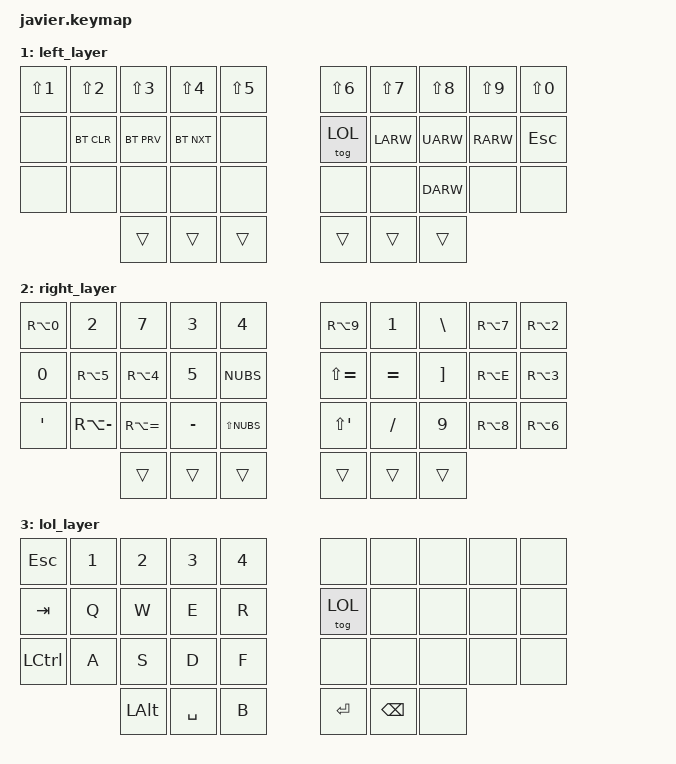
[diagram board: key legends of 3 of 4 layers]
#include <behaviors.dtsi>
#include <dt-bindings/zmk/keys.h>
#include <dt-bindings/zmk/bt.h>

#define DEF 0
#define LEF 1
#define RIG 2
// #define TRI 3
#define LOL 3

// Home row mod macros
#define HRML(k1,k2,k3,k4) &ht LSHIFT k1 &ht LGUI k2  &ht LCTRL k3  &ht LSHIFT k4
#define HRMR(k1,k2,k3,k4) &ht RSHIFT k1  &ht RCTRL k2  &ht RALT k3 &ht RSHIFT k4

/ {
    behaviors {
        ht: hold_tap {
            label = "hold_tap";
            compatible = "zmk,behavior-hold-tap";
            #binding-cells = <2>;
            flavor = "balanced";
            tapping-term-ms = <200>;
            bindings = <&kp>, <&kp>;
        };

        dashes: dashes {
            compatible = "zmk,behavior-mod-morph";
            #binding-cells = <0>;
            bindings = <&kp N6>, <&kp N8>;
            mods = <(MOD_LSFT|MOD_RSFT)>;
            keep-mods = <(MOD_RSFT)>;
        };
    };
    // conditional_layers {
    //     compatible = "zmk,conditional-layers";
    //     tri_layer {
    //         if-layers = <RIG LEF>;
    //         then-layer = <TRI>;
    //     };
    // };

    keymap {
        compatible = "zmk,keymap";

        default_layer {
            bindings = <
        //╭──────────┬──────────┬──────────┬──────────┬──────────╮   ╭──────────┬──────────┬──────────┬──────────┬──────────╮
        //│  A       │  Z       │  E       │  R       │  T       │   │  Y       │  U       │  I       │  O       │  P       │
            &kp Q      &kp W      &kp E      &kp R      &kp T          &kp Y      &kp U      &kp I      &kp O      &kp P
        //├──────────┼──────────┼──────────┼──────────┼──────────┤   ├──────────┼──────────┼──────────┼──────────┼──────────┤
        //│  Q       │  S       │  D       │  F       │  G       │   │  H       │  J       │  K       │  L       │  M       │
            HRML(A,     S,         D,         F)        &kp G          &kp H      HRMR(J,     K,         L,         SEMI)
        //├──────────┼──────────┼──────────┼──────────┼──────────┤   ├──────────┼──────────┼──────────┼──────────┼──────────┤
        //│  W       │  X       │  C       │  V       │  B       │   │  N       │  , ?     │  ; .     │  : /     │   - _    │
          &ht LCTRL Z   &kp X      &kp C      &kp V      &kp B          &kp N     &kp M      &kp COMMA    &kp DOT   &dashes
        //╰──────────┴──────────┴──────────┼──────────┼──────────┤   ├──────────┼──────────┼──────────┴──────────┴──────────╯
                                &ht LCTRL ESC &kp SPACE &lt LEF TAB   &lt RIG RET  &kp BSPC  &kp LALT
        //                      ╰──────────┴──────────┴──────────╯   ╰──────────┴──────────┴──────────╯
            >;
        };

        left_layer {
            bindings = <
        //╭──────────┬──────────┬──────────┬──────────┬──────────╮   ╭──────────┬──────────┬──────────┬──────────┬──────────╮
        //│ 1        │  2       │  3       │  4       │  5       │   │ 6        │ 7        │ 8        │ 9        │   0      │
          &kp LS(N1)  &kp LS(N2) &kp LS(N3) &kp LS(N4) &kp LS(N5)     &kp LS(N6) &kp LS(N7) &kp LS(N8) &kp LS(N9) &kp LS(N0)
        //├──────────┼──────────┼──────────┼──────────┼──────────┤   ├──────────┼──────────┼──────────┼──────────┼──────────┤
        //│          │ BT CLEAR │ BT PREV  │ BT NEXT  │          |   | LOL      │ LEFT     │ UP       │ RIGHT    │ ESC      │
            &none     &bt BT_CLR &bt BT_PRV &bt BT_NXT &none           &tog LOL  &kp LARW   &kp UARW   &kp RARW   &kp ESC 
        //├──────────┼──────────┼──────────┼──────────┼──────────┤   ├──────────┼──────────┼──────────┼──────────┼──────────┤
        //│          │          │          │          │          │   │          │          │ DOWN     │          │          │
            &none     &none      &none      &none       &none          &none      &none      &kp DARW   &none      &none 
        //╰──────────┴──────────┴──────────┼──────────┼──────────┤   ├──────────┼──────────┼──────────┴──────────┴──────────╯
                                  &trans     &trans     &trans         &trans     &trans     &trans  
        //                      ╰──────────┴──────────┴──────────╯   ╰──────────┴──────────┴──────────╯
            >;
        };

        right_layer {
            bindings = <
        //╭──────────┬──────────┬──────────┬──────────┬──────────╮   ╭──────────┬──────────┬──────────┬──────────┬──────────╮
        //│  @       │  é       │  è       │  "       │  '       │   │  ^       │  &       │  *       │  `       │  ~       │
          &kp RA(N0)    &kp N2     &kp N7    &kp N3     &kp N4        &kp RA(N9)   &kp N1    &kp BSLH  &kp RA(N7) &kp RA(N2)
        //├──────────┼──────────┼──────────┼──────────┼──────────┤   ├──────────┼──────────┼──────────┼──────────┼──────────┤
        //│  à       │  [       │  {       │  (       │   <      │   │  +       │  =       │  $       │   €      │  #       │
            &kp N0    &kp RA(N5)  &kp RA(N4)   &kp N5   &kp NUBS    &kp LS(EQUAL) &kp EQUAL  &kp RBKT  &kp RA(E)   &kp RA(N3)
        //├──────────┼──────────┼──────────┼──────────┼──────────┤   ├──────────┼──────────┼──────────┼──────────┼──────────┤
        //│  ù       │  ]       │  }       │  )       │   >      │   │   %      │  !       │  ç       │  \       │   |      │
           &kp SQT  &kp RA(MINUS) &kp RA(EQUAL) &kp MINUS &kp LS(NUBS) &kp LS(SQT) &kp FSLH  &kp N9    &kp RA(N8) &kp RA(N6)
        //╰──────────┴──────────┴──────────┼──────────┼──────────┤   ├──────────┼──────────┼──────────┴──────────┴──────────╯
                                  &trans     &trans     &trans         &trans     &trans     &trans 
        //                      ╰──────────┴──────────┴──────────╯   ╰──────────┴──────────┴──────────╯
            >;
        };

        lol_layer {
            bindings = <
        //╭──────────┬──────────┬──────────┬──────────┬──────────╮   ╭──────────┬──────────┬──────────┬──────────┬──────────╮
        //│ ESC      │  1       │  2       │  3       │  4       │   │          │          │          │          │          │
           &kp ESC    &kp N1     &kp N2     &kp N3      &kp N4         &none      &none       &none      &none      &none
        //├──────────┼──────────┼──────────┼──────────┼──────────┤   ├──────────┼──────────┼──────────┼──────────┼──────────┤
        //│  TAB     │  A       │  Z       │  E       │  R       |   | LOL      │          │          │          │          │
            &kp TAB    &kp Q      &kp W      &kp E     &kp R           &tog LOL   &none      &none      &none      &none 
        //├──────────┼──────────┼──────────┼──────────┼──────────┤   ├──────────┼──────────┼──────────┼──────────┼──────────┤
        //│  CTRL    │  Q       │  S       │   D      │  F       │   │          │          │          │          │          │
            &kp LCTL    &kp A     &kp S      &kp D      &kp F         &none      &none      &none       &none      &none 
        //╰──────────┴──────────┴──────────┼──────────┼──────────┤   ├──────────┼──────────┼──────────┴──────────┴──────────╯
                                  &kp LALT   &kp SPACE  &kp B         &kp RET     &kp BSPC   &none  
        //                      ╰──────────┴──────────┴──────────╯   ╰──────────┴──────────┴──────────╯
            >;
        };
        

        // tri_layer {
        //     bindings = <
        // //╭──────────┬──────────┬──────────┬───────────┬────────────╮   ╭────────────┬────────────┬──────────┬───────────┬──────────╮
        // //│  F1      │  F2      │  F3      │  F4       │ PROFILE 0  │   │ PROFILE 2  │ TOGGLEOUT  │ WINDOWS  │ VOL MUTE  │ NEXTSONG │
        //     &kp F1     &kp F2     &kp F3     &kp F4     &bt BT_SEL 0     &bt BT_SEL 2  &out OUT_TOG &tog WIN  &kp C_MUTE  &kp C_NEXT
        // //├──────────┼──────────┼──────────┼───────────┼────────────┤   ├────────────┼────────────┼──────────┼───────────┼──────────┤
        // //│  F5      │  F6      │  F7      │  F8       │ PROFILE 1  │   │ PROFILE 3  │ INC BRIGHT │          │  VOL UP   │PAUSEMUSIC│
        //     &kp F5     &kp F6     &kp F7     &kp F8     &bt BT_SEL 1     &bt BT_SEL 3  &kp C_BRI_UP  &none    &kp C_VOL_UP  &kp C_PP
        // //├──────────┼──────────┼──────────┼───────────┼────────────┤   ├────────────┼────────────┼──────────┼───────────┼──────────┤
        // //│  F9      │  F10     │  F11     │  F12      │  CLEAR BT  │   │ PROFILE 4  │ DEC BRIGHT │          |  VOL DOWN │ PREVSONG │
        //     &kp F9     &kp F10    &kp F11    &kp F12     &bt BT_CLR      &bt BT_SEL 4  &kp C_BRI_DEC  &none    &kp C_VOL_DN &kp C_PREV
        // //╰──────────┴──────────┴──────────┼───────────┼────────────┤   ├────────────┼────────────┼──────────┴───────────┴──────────╯
        //                           &none      &none       &none            &none        &none        &none 
        // //                      ╰──────────┴───────────┴────────────╯   ╰────────────┴────────────┴──────────╯
        //     >;
        // };
    };
};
